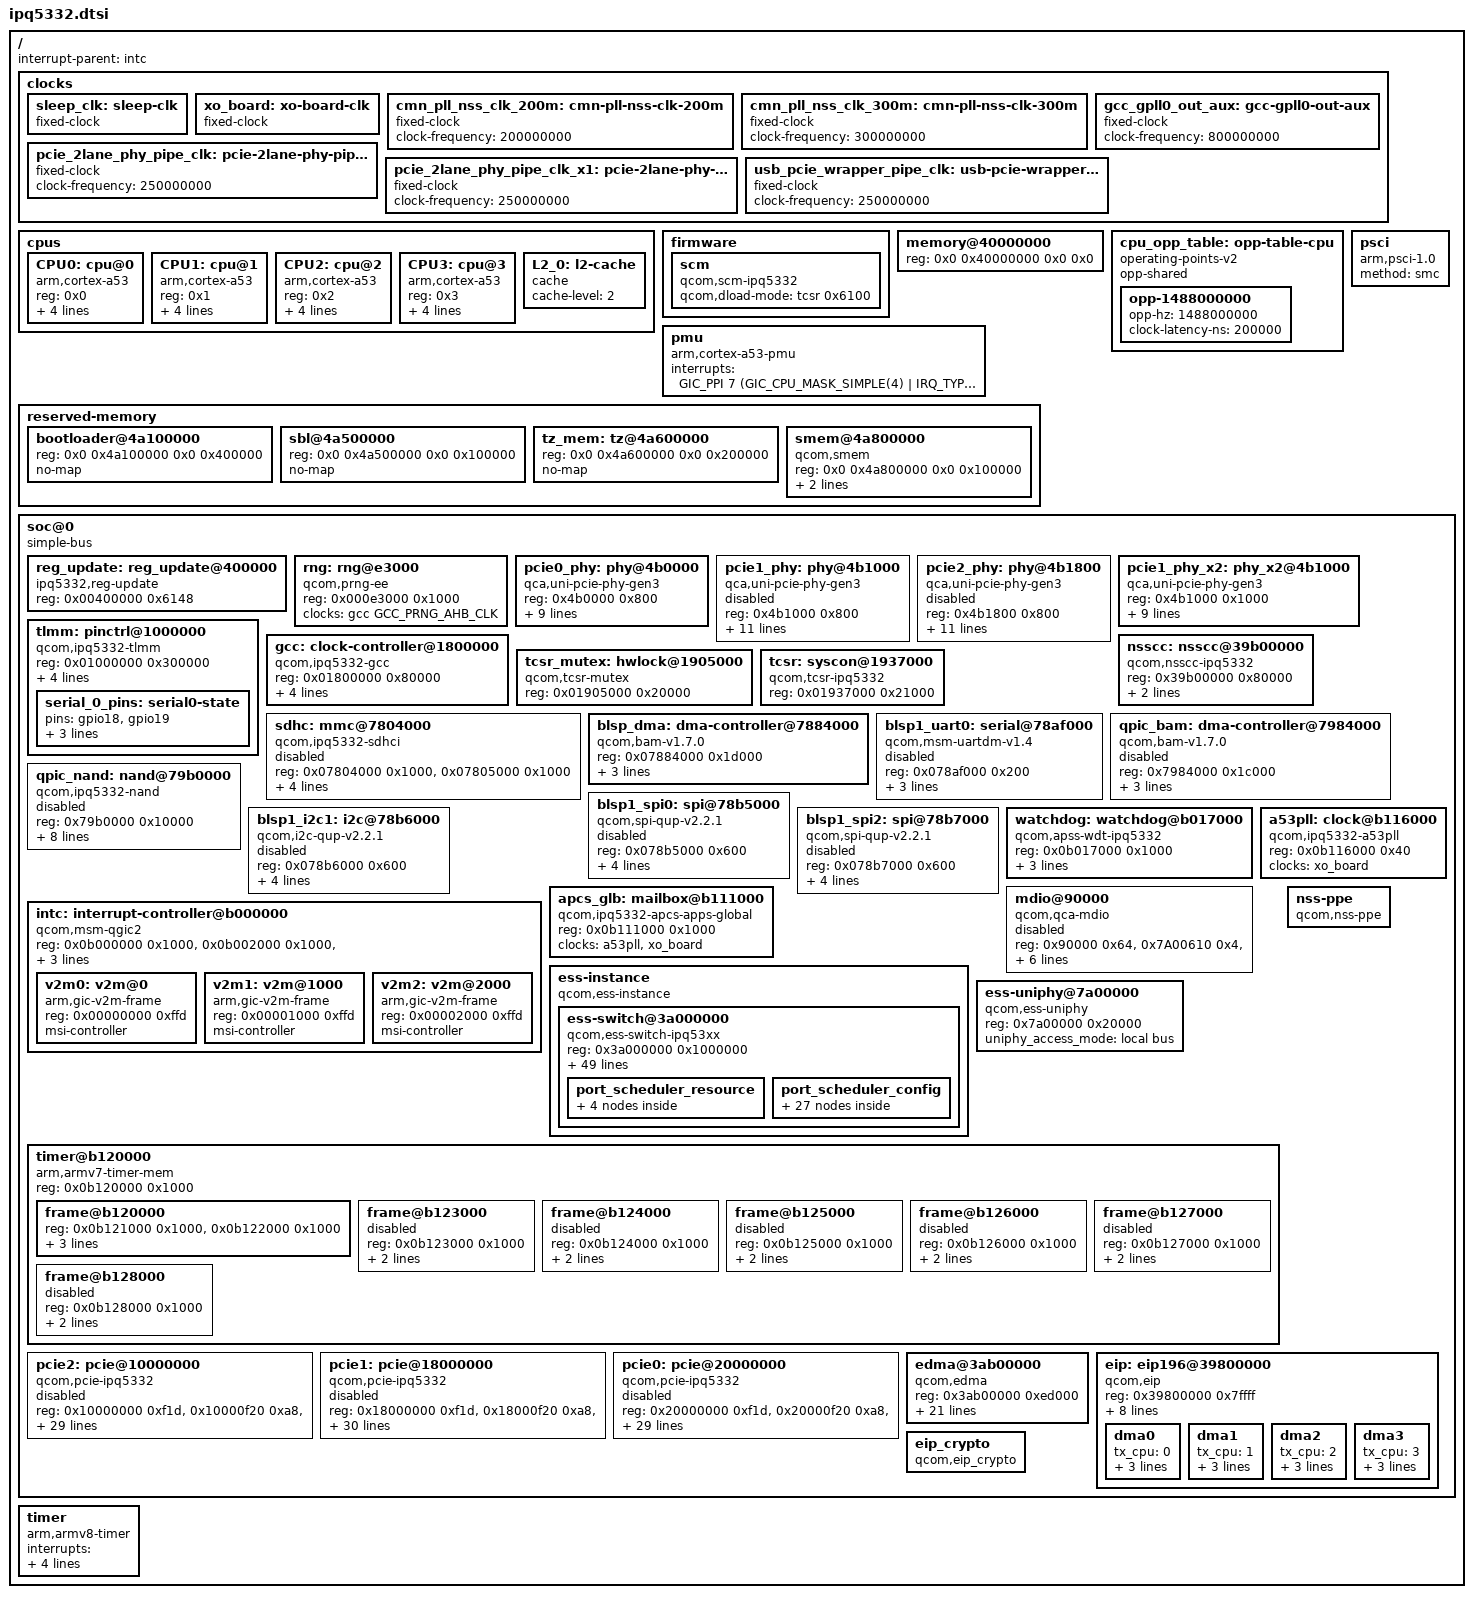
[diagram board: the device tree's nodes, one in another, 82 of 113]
// SPDX-License-Identifier: BSD-3-Clause
/*
 * IPQ5332 device tree source
 *
 * Copyright (c) 2022-2023 Qualcomm Innovation Center, Inc. All rights reserved.
 */

#include <dt-bindings/clock/qcom,apss-ipq.h>
#include <dt-bindings/clock/qcom,ipq5332-gcc.h>
#include <dt-bindings/clock/qcom,nsscc-ipq5332.h>
#include <dt-bindings/reset/qcom,nsscc-ipq5332.h>
#include <dt-bindings/interrupt-controller/arm-gic.h>

/ {
	interrupt-parent = <&intc>;
	#address-cells = <2>;
	#size-cells = <2>;

	clocks {
		sleep_clk: sleep-clk {
			compatible = "fixed-clock";
			#clock-cells = <0>;
		};

		xo_board: xo-board-clk {
			compatible = "fixed-clock";
			#clock-cells = <0>;
		};

		cmn_pll_nss_clk_200m: cmn-pll-nss-clk-200m {
			compatible = "fixed-clock";
			clock-frequency = <200000000>;
			#clock-cells = <0>;
		};

		cmn_pll_nss_clk_300m: cmn-pll-nss-clk-300m {
			compatible = "fixed-clock";
			clock-frequency = <300000000>;
			#clock-cells = <0>;
		};

		gcc_gpll0_out_aux: gcc-gpll0-out-aux {
			compatible = "fixed-clock";
			clock-frequency = <800000000>;
			#clock-cells = <0>;
		};

		pcie_2lane_phy_pipe_clk: pcie-2lane-phy-pipe-clk {
			compatible = "fixed-clock";
			clock-frequency = <250000000>;
			#clock-cells = <0>;
		};

		pcie_2lane_phy_pipe_clk_x1: pcie-2lane-phy-pipe-clk-x1 {
			compatible = "fixed-clock";
			clock-frequency = <250000000>;
			#clock-cells = <0>;
		};

		usb_pcie_wrapper_pipe_clk: usb-pcie-wrapper-pipe-clk {
			compatible = "fixed-clock";
			clock-frequency = <250000000>;
			#clock-cells = <0>;
		};
	};

	cpus {
		#address-cells = <1>;
		#size-cells = <0>;

		CPU0: cpu@0 {
			device_type = "cpu";
			compatible = "arm,cortex-a53";
			reg = <0x0>;
			enable-method = "psci";
			next-level-cache = <&L2_0>;
			clocks = <&apcs_glb APCS_ALIAS0_CORE_CLK>;
			operating-points-v2 = <&cpu_opp_table>;
		};

		CPU1: cpu@1 {
			device_type = "cpu";
			compatible = "arm,cortex-a53";
			reg = <0x1>;
			enable-method = "psci";
			next-level-cache = <&L2_0>;
			clocks = <&apcs_glb APCS_ALIAS0_CORE_CLK>;
			operating-points-v2 = <&cpu_opp_table>;
		};

		CPU2: cpu@2 {
			device_type = "cpu";
			compatible = "arm,cortex-a53";
			reg = <0x2>;
			enable-method = "psci";
			next-level-cache = <&L2_0>;
			clocks = <&apcs_glb APCS_ALIAS0_CORE_CLK>;
			operating-points-v2 = <&cpu_opp_table>;
		};

		CPU3: cpu@3 {
			device_type = "cpu";
			compatible = "arm,cortex-a53";
			reg = <0x3>;
			enable-method = "psci";
			next-level-cache = <&L2_0>;
			clocks = <&apcs_glb APCS_ALIAS0_CORE_CLK>;
			operating-points-v2 = <&cpu_opp_table>;
		};

		L2_0: l2-cache {
			compatible = "cache";
			cache-level = <2>;
		};
	};

	firmware {
		scm {
			compatible = "qcom,scm-ipq5332", "qcom,scm";
			qcom,dload-mode = <&tcsr 0x6100>;
		};
	};

	memory@40000000 {
		device_type = "memory";
		/* We expect the bootloader to fill in the size */
		reg = <0x0 0x40000000 0x0 0x0>;
	};

	cpu_opp_table: opp-table-cpu {
		compatible = "operating-points-v2";
		opp-shared;

		opp-1488000000 {
			opp-hz = /bits/ 64 <1488000000>;
			clock-latency-ns = <200000>;
		};
	};

	pmu {
		compatible = "arm,cortex-a53-pmu";
		interrupts = <GIC_PPI 7 (GIC_CPU_MASK_SIMPLE(4) | IRQ_TYPE_LEVEL_HIGH)>;
	};

	psci {
		compatible = "arm,psci-1.0";
		method = "smc";
	};

	reserved-memory {
		#address-cells = <2>;
		#size-cells = <2>;
		ranges;

		bootloader@4a100000 {
			reg = <0x0 0x4a100000 0x0 0x400000>;
			no-map;
		};

		sbl@4a500000 {
			reg = <0x0 0x4a500000 0x0 0x100000>;
			no-map;
		};

		tz_mem: tz@4a600000 {
			reg = <0x0 0x4a600000 0x0 0x200000>;
			no-map;
		};

		smem@4a800000 {
			compatible = "qcom,smem";
			reg = <0x0 0x4a800000 0x0 0x100000>;
			no-map;

			hwlocks = <&tcsr_mutex 0>;
		};
	};

	soc@0 {
		compatible = "simple-bus";
		#address-cells = <1>;
		#size-cells = <1>;
		ranges = <0 0 0 0xffffffff>;

		reg_update: reg_update@400000 {
			compatible = "ipq5332,reg-update";
			reg = <0x00400000 0x6148>;
			reg-names = "memnoc";
			status = "ok";
		};

		rng: rng@e3000 {
			compatible = "qcom,prng-ee";
			reg = <0x000e3000 0x1000>;
			clocks = <&gcc GCC_PRNG_AHB_CLK>;
			clock-names = "core";
		};

		pcie0_phy: phy@4b0000 {
			compatible = "qca,uni-pcie-phy-gen3";
			reg = <0x4b0000 0x800>;
			phy-type = "gen3";
			#phy-cells = <0>;
			clocks = <&gcc GCC_PCIE3X1_0_PIPE_CLK>,
				<&gcc GCC_SNOC_PCIE3_1LANE_M_CLK>,
				<&gcc GCC_SNOC_PCIE3_1LANE_S_CLK>,
				<&gcc GCC_PCIE3X1_PHY_AHB_CLK>;

			clock-names = "pipe_clk",
					"lane_m_clk",
					"lane_s_clk",
					"phy_ahb_clk";

			resets = <&gcc GCC_PCIE3X1_0_PHY_BCR>,
				<&gcc GCC_PCIE3X1_0_PHY_PHY_BCR>,
				<&gcc GCC_PCIE3X1_PHY_AHB_CLK_ARES>;
			reset-names = "phy",
					"phy_phy",
					"phy_ahb";
			mode-fixed = <2>; /* TBD */
			/*status = "disabled";*/
		};

		/* PHY for PCIE1 single lane mode */
		pcie1_phy: phy@4b1000 {
			compatible = "qca,uni-pcie-phy-gen3";
			reg = <0x4b1000 0x800>;
			phy-type = "gen3";
			#phy-cells = <0>;
			qti,multiplexed-phy;
			qti,phy-mux-regs = <&tcsr 0x10544>;
			phy-ahb-shared-reset;
			clocks = <&gcc GCC_PCIE3X2_PIPE_CLK>,
				<&gcc GCC_SNOC_PCIE3_2LANE_M_CLK>,
				<&gcc GCC_SNOC_PCIE3_2LANE_S_CLK>,
				<&gcc GCC_PCIE3X2_PHY_AHB_CLK>;

			clock-names = "pipe_clk",
					"lane_m_clk",
					"lane_s_clk",
					"phy_ahb_clk";

			resets = <&gcc GCC_PCIE3X2_PHY_BCR>,
				<&gcc GCC_PCIE3X2_PHY_AHB_CLK_ARES>;
			reset-names = "phy",
					"phy_ahb";
			mode-fixed = <2>; /* TBD */
			status = "disabled";
		};

		/* PHY for PCIE2 single lane mode */
		pcie2_phy: phy@4b1800 {
			compatible = "qca,uni-pcie-phy-gen3";
			reg = <0x4b1800 0x800>;
			phy-type = "gen3";
			#phy-cells = <0>;
			phy-ahb-shared-reset;

			qti,multiplexed-phy;
			qti,phy-mux-regs = <&tcsr 0x10544>;

			clocks = <&gcc GCC_PCIE3X1_1_PIPE_CLK>,
				<&gcc GCC_SNOC_PCIE3_1LANE_1_M_CLK>,
				<&gcc GCC_SNOC_PCIE3_1LANE_1_S_CLK>,
				<&gcc GCC_PCIE3X2_PHY_AHB_CLK>;

			clock-names = "pipe_clk",
					"lane_m_clk",
					"lane_s_clk",
					"phy_ahb_clk";

			resets = <&gcc GCC_PCIE3X1_1_PHY_BCR>,
				<&gcc GCC_PCIE3X2_PHY_AHB_CLK_ARES>;
			reset-names = "phy",
					"phy_ahb";
			mode-fixed = <2>; /* TBD */
			status = "disabled";
		};

		/* PHY for PCIE1 dual lane mode */
		pcie1_phy_x2: phy_x2@4b1000 {
			compatible = "qca,uni-pcie-phy-gen3";
			reg = <0x4b1000 0x1000>;
			phy-type = "gen3";
			#phy-cells = <0>;
			clocks = <&gcc GCC_PCIE3X2_PIPE_CLK>,
				<&gcc GCC_SNOC_PCIE3_2LANE_M_CLK>,
				<&gcc GCC_SNOC_PCIE3_2LANE_S_CLK>,
				<&gcc GCC_PCIE3X2_PHY_AHB_CLK>;

			clock-names = "pipe_clk",
					"lane_m_clk",
					"lane_s_clk",
					"phy_ahb_clk";

			resets = <&gcc GCC_PCIE3X2_PHY_BCR>,
				<&gcc GCC_PCIE3X2_PHY_AHB_CLK_ARES>;
			reset-names = "phy",
					"phy_ahb";
			mode-fixed = <2>; /* TBD */
			x2 = <1>;
			/*status = "disabled";*/
		};

		tlmm: pinctrl@1000000 {
			compatible = "qcom,ipq5332-tlmm";
			reg = <0x01000000 0x300000>;
			interrupts = <GIC_SPI 249 IRQ_TYPE_LEVEL_HIGH>;
			gpio-controller;
			#gpio-cells = <2>;
			gpio-ranges = <&tlmm 0 0 53>;
			interrupt-controller;
			#interrupt-cells = <2>;

			serial_0_pins: serial0-state {
				pins = "gpio18", "gpio19";
				function = "blsp0_uart0";
				drive-strength = <8>;
				bias-pull-up;
			};
		};

		gcc: clock-controller@1800000 {
			compatible = "qcom,ipq5332-gcc";
			reg = <0x01800000 0x80000>;
			#clock-cells = <1>;
			#reset-cells = <1>;
			#power-domain-cells = <1>;
			clocks = <&xo_board>,
				 <&sleep_clk>,
				 <&pcie_2lane_phy_pipe_clk>,
				 <&pcie_2lane_phy_pipe_clk_x1>,
				 <&usb_pcie_wrapper_pipe_clk>;
		};

		nsscc: nsscc@39b00000{
			compatible = "qcom,nsscc-ipq5332";
			reg = <0x39b00000 0x80000>;
			clocks = <&xo_board>,
				<&cmn_pll_nss_clk_200m>,
				<&cmn_pll_nss_clk_300m>,
				<&gcc_gpll0_out_aux>;
			clock-names = "xo",
					"cmn_pll_nss_clk_200m",
					"cmn_pll_nss_clk_300m",
					"gcc_gpll0_out_aux";
			#clock-cells = <0x1>;
			#reset-cells = <0x1>;
		};

		tcsr_mutex: hwlock@1905000 {
			compatible = "qcom,tcsr-mutex";
			reg = <0x01905000 0x20000>;
			#hwlock-cells = <1>;
		};

		tcsr: syscon@1937000 {
			compatible = "qcom,tcsr-ipq5332", "syscon";
			reg = <0x01937000 0x21000>;
		};

		sdhc: mmc@7804000 {
			compatible = "qcom,ipq5332-sdhci", "qcom,sdhci-msm-v5";
			reg = <0x07804000 0x1000>, <0x07805000 0x1000>;

			interrupts = <GIC_SPI 313 IRQ_TYPE_LEVEL_HIGH>,
				     <GIC_SPI 316 IRQ_TYPE_LEVEL_HIGH>;
			interrupt-names = "hc_irq", "pwr_irq";

			clocks = <&gcc GCC_SDCC1_AHB_CLK>,
				 <&gcc GCC_SDCC1_APPS_CLK>,
				 <&xo_board>;
			clock-names = "iface", "core", "xo";
			status = "disabled";
		};

		blsp_dma: dma-controller@7884000 {
			compatible = "qcom,bam-v1.7.0";
			reg = <0x07884000 0x1d000>;
			interrupts = <GIC_SPI 289 IRQ_TYPE_LEVEL_HIGH>;
			clocks = <&gcc GCC_BLSP1_AHB_CLK>;
			clock-names = "bam_clk";
			#dma-cells = <1>;
			qcom,ee = <0>;
		};

		blsp1_uart0: serial@78af000 {
			compatible = "qcom,msm-uartdm-v1.4", "qcom,msm-uartdm";
			reg = <0x078af000 0x200>;
			interrupts = <GIC_SPI 290 IRQ_TYPE_LEVEL_HIGH>;
			clocks = <&gcc GCC_BLSP1_UART1_APPS_CLK>,
				 <&gcc GCC_BLSP1_AHB_CLK>;
			clock-names = "core", "iface";
			status = "disabled";
		};

		qpic_bam: dma-controller@7984000 {
			compatible = "qcom,bam-v1.7.0";
			reg = <0x7984000 0x1c000>;
			interrupts = <GIC_SPI 66 IRQ_TYPE_LEVEL_HIGH>;
			clocks = <&gcc GCC_QPIC_AHB_CLK>;
			clock-names = "bam_clk";
			#dma-cells = <1>;
			qcom,ee = <0>;
			status = "disabled";
		};

		qpic_nand: nand@79b0000 {
			compatible = "qcom,ipq5332-nand";
			reg = <0x79b0000 0x10000>;
			#address-cells = <1>;
			#size-cells = <0>;
			clocks = <&gcc GCC_QPIC_CLK>,
				<&gcc GCC_QPIC_AHB_CLK>,
				<&gcc GCC_QPIC_IO_MACRO_CLK>;
			clock-names = "core", "aon", "io_macro";

			dmas = <&qpic_bam 0>,
				<&qpic_bam 1>,
				<&qpic_bam 2>,
				<&qpic_bam 3>;
			dma-names = "tx", "rx", "cmd", "sts";
			qcom,io_macro_max_clk = <320000000>;
			qcom,io_macro_clk_rates = <24000000 100000000 200000000 \
						  320000000>;
			status = "disabled";
		};

		blsp1_spi0: spi@78b5000 {
			compatible = "qcom,spi-qup-v2.2.1";
			reg = <0x078b5000 0x600>;
			#address-cells = <1>;
			#size-cells = <0>;
			interrupts = <GIC_SPI 292 IRQ_TYPE_LEVEL_HIGH>;
			clocks = <&gcc GCC_BLSP1_QUP1_SPI_APPS_CLK>,
			         <&gcc GCC_BLSP1_AHB_CLK>;
			clock-names = "core", "iface";
			dmas = <&blsp_dma 4>, <&blsp_dma 5>;
			dma-names = "tx", "rx";
			status = "disabled";
		};

		blsp1_i2c1: i2c@78b6000 {
			compatible = "qcom,i2c-qup-v2.2.1";
			reg = <0x078b6000 0x600>;
			#address-cells = <1>;
			#size-cells = <0>;
			interrupts = <GIC_SPI 293 IRQ_TYPE_LEVEL_HIGH>;
			clocks = <&gcc GCC_BLSP1_QUP2_I2C_APPS_CLK>,
			         <&gcc GCC_BLSP1_AHB_CLK>;
			clock-names = "core", "iface";
			dmas = <&blsp_dma 6>, <&blsp_dma 7>;
			dma-names = "tx", "rx";
			status = "disabled";
		};

		blsp1_spi2: spi@78b7000 {
			compatible = "qcom,spi-qup-v2.2.1";
			reg = <0x078b7000 0x600>;
			#address-cells = <1>;
			#size-cells = <0>;
			interrupts = <GIC_SPI 294 IRQ_TYPE_LEVEL_HIGH>;
			clocks = <&gcc GCC_BLSP1_QUP3_SPI_APPS_CLK>,
				 <&gcc GCC_BLSP1_AHB_CLK>;
			clock-names = "core", "iface";
			dmas = <&blsp_dma 8>, <&blsp_dma 9>;
			dma-names = "tx", "rx";
			status = "disabled";
		};

		intc: interrupt-controller@b000000 {
			compatible = "qcom,msm-qgic2";
			reg = <0x0b000000 0x1000>,	/* GICD */
			      <0x0b002000 0x1000>,	/* GICC */
			      <0x0b001000 0x1000>,	/* GICH */
			      <0x0b004000 0x1000>;	/* GICV */
			interrupts = <GIC_PPI 9 IRQ_TYPE_LEVEL_HIGH>;
			interrupt-controller;
			#interrupt-cells = <3>;
			#address-cells = <1>;
			#size-cells = <1>;
			ranges = <0 0x0b00c000 0x3000>;

			v2m0: v2m@0 {
				compatible = "arm,gic-v2m-frame";
				reg = <0x00000000 0xffd>;
				msi-controller;
			};

			v2m1: v2m@1000 {
				compatible = "arm,gic-v2m-frame";
				reg = <0x00001000 0xffd>;
				msi-controller;
			};

			v2m2: v2m@2000 {
				compatible = "arm,gic-v2m-frame";
				reg = <0x00002000 0xffd>;
				msi-controller;
			};
		};

		watchdog: watchdog@b017000 {
			compatible = "qcom,apss-wdt-ipq5332", "qcom,kpss-wdt";
			reg = <0x0b017000 0x1000>;
			interrupts = <GIC_SPI 3 IRQ_TYPE_EDGE_RISING>;
			clocks = <&sleep_clk>;
			timeout-sec = <30>;
		};

		apcs_glb: mailbox@b111000 {
			compatible = "qcom,ipq5332-apcs-apps-global",
				     "qcom,ipq6018-apcs-apps-global";
			reg = <0x0b111000 0x1000>;
			#clock-cells = <1>;
			clocks = <&a53pll>, <&xo_board>;
			clock-names = "pll", "xo";
			#mbox-cells = <1>;
		};

		a53pll: clock@b116000 {
			compatible = "qcom,ipq5332-a53pll";
			reg = <0x0b116000 0x40>;
			#clock-cells = <0>;
			clocks = <&xo_board>;
			clock-names = "xo";
		};

		mdio@90000 {
			compatible = "qcom,qca-mdio", "qcom,ipq40xx-mdio";
			reg = <0x90000 0x64>, <0x7A00610 0x4>, <0x7A10610 0x4>;
			#address-cells = <1>;
			#size-cells = <1>;
			clocks = <&gcc GCC_MDIO_AHB_CLK>,
			       <&gcc GCC_UNIPHY0_AHB_CLK>,
			       <&gcc GCC_UNIPHY0_SYS_CLK>,
			       <&gcc GCC_UNIPHY1_AHB_CLK>,
			       <&gcc GCC_UNIPHY1_SYS_CLK>;
			clock-names = "gcc_mdio_ahb_clk",
				"uniphy0_ahb_clk",
				"uniphy0_sys_clk",
				"uniphy1_ahb_clk",
				"uniphy1_sys_clk";
			status = "disabled";
		};

		ess-instance {
			compatible = "qcom,ess-instance";
			ess-switch@3a000000 {
				compatible = "qcom,ess-switch-ipq53xx";
				reg = <0x3a000000 0x1000000>;
				switch_access_mode = "local bus";
				bm_tick_mode = <0>; /* bm tick mode */
				tm_tick_mode = <0>; /* tm tick mode */
				clocks = <&gcc GCC_CMN_12GPLL_AHB_CLK>,
					<&gcc GCC_CMN_12GPLL_SYS_CLK>,
					<&gcc GCC_UNIPHY0_AHB_CLK>,
					<&gcc GCC_UNIPHY0_SYS_CLK>,
					<&gcc GCC_UNIPHY1_AHB_CLK>,
					<&gcc GCC_UNIPHY1_SYS_CLK>,
					<&gcc GCC_NSSNOC_NSSCC_CLK>,
					<&gcc GCC_NSSCC_CLK>,
					<&gcc GCC_NSSNOC_SNOC_1_CLK>,
					<&gcc GCC_NSSNOC_SNOC_CLK>,
					<&gcc GCC_IM_SLEEP_CLK>,
					<&nsscc NSS_CC_PORT1_MAC_CLK>,
					<&nsscc NSS_CC_PORT2_MAC_CLK>,
					<&nsscc NSS_CC_PPE_SWITCH_CLK>,
					<&nsscc NSS_CC_PPE_SWITCH_CFG_CLK>,
					<&nsscc NSS_CC_NSSNOC_PPE_CLK>,
					<&nsscc NSS_CC_NSSNOC_PPE_CFG_CLK>,
					<&nsscc NSS_CC_PPE_EDMA_CLK>,
					<&nsscc NSS_CC_PPE_EDMA_CFG_CLK>,
					<&nsscc NSS_CC_PPE_SWITCH_IPE_CLK>,
					<&nsscc NSS_CC_PPE_SWITCH_BTQ_CLK>,
					<&nsscc NSS_CC_PORT1_RX_CLK>,
					<&nsscc NSS_CC_PORT1_TX_CLK>,
					<&nsscc NSS_CC_PORT2_RX_CLK>,
					<&nsscc NSS_CC_PORT2_TX_CLK>,
					<&nsscc NSS_CC_UNIPHY_PORT1_RX_CLK>,
					<&nsscc NSS_CC_UNIPHY_PORT1_TX_CLK>,
					<&nsscc NSS_CC_UNIPHY_PORT2_RX_CLK>,
					<&nsscc NSS_CC_UNIPHY_PORT2_TX_CLK>;
				clock-names = "cmn_ahb_clk",
					"cmn_sys_clk",
					"uniphy0_ahb_clk",
					"uniphy0_sys_clk",
					"uniphy1_ahb_clk",
					"uniphy1_sys_clk",
					"gcc_nssnoc_nsscc_clk",
					"gcc_nsscc_clk",
					"gcc_nssnoc_snoc_1_clk",
					"gcc_nssnoc_snoc_clk",
					"gcc_im_sleep_clk",
					"port1_mac_clk",
					"port2_mac_clk",
					"nss_ppe_clk",
					"nss_ppe_cfg_clk",
					"nssnoc_ppe_clk",
					"nssnoc_ppe_cfg_clk",
					"nss_edma_clk",
					"nss_edma_cfg_clk",
					"nss_ppe_ipe_clk",
					"nss_ppe_btq_clk",
					"nss_port1_rx_clk",
					"nss_port1_tx_clk",
					"nss_port2_rx_clk",
					"nss_port2_tx_clk",
					"uniphy0_port1_rx_clk",
					"uniphy0_port1_tx_clk",
					"uniphy1_port5_rx_clk",
					"uniphy1_port5_tx_clk";
				resets = <&nsscc NSS_CC_PPE_BCR>,
					<&gcc GCC_UNIPHY0_BCR>,
					<&gcc GCC_UNIPHY1_BCR>,
					<&gcc GCC_UNIPHY0_AHB_CLK_ARES>,
					<&gcc GCC_UNIPHY1_AHB_CLK_ARES>,
					<&gcc GCC_UNIPHY0_SYS_CLK_ARES>,
					<&gcc GCC_UNIPHY1_SYS_CLK_ARES>,
					<&gcc GCC_UNIPHY0_XPCS_ARES>,
					<&gcc GCC_UNIPHY1_XPCS_ARES>,
					<&nsscc NSS_CC_UNIPHY_PORT1_RX_CLK_ARES>,
					<&nsscc NSS_CC_UNIPHY_PORT1_TX_CLK_ARES>,
					<&nsscc NSS_CC_UNIPHY_PORT2_RX_CLK_ARES>,
					<&nsscc NSS_CC_UNIPHY_PORT2_TX_CLK_ARES>,
					<&nsscc NSS_CC_PORT1_RX_CLK_ARES>,
					<&nsscc NSS_CC_PORT1_TX_CLK_ARES>,
					<&nsscc NSS_CC_PORT2_RX_CLK_ARES>,
					<&nsscc NSS_CC_PORT2_TX_CLK_ARES>,
					<&nsscc NSS_CC_PORT1_MAC_CLK_ARES>,
					<&nsscc NSS_CC_PORT2_MAC_CLK_ARES>;
				reset-names = "ppe_rst",
					"uniphy0_soft_rst",
					"uniphy1_soft_rst",
					"uniphy0_ahb_rst",
					"uniphy1_ahb_rst",
					"uniphy0_sys_rst",
					"uniphy1_sys_rst",
					"uniphy0_xpcs_rst",
					"uniphy1_xpcs_rst",
					"uniphy_port1_rx_rst",
					"uniphy_port1_tx_rst",
					"uniphy_port2_rx_rst",
					"uniphy_port2_tx_rst",
					"nss_port1_rx_rst",
					"nss_port1_tx_rst",
					"nss_port2_rx_rst",
					"nss_port2_tx_rst",
					"nss_port1_mac_rst",
					"nss_port2_mac_rst";

				port_scheduler_resource {
					port@0 {
						port_id = <0>;
						ucast_queue = <0 43>;
						mcast_queue = <256 262>;
						l0sp = <0 6>;
						l0cdrr = <0 27>;
						l0edrr = <0 27>;
						l1cdrr = <0 0>;
						l1edrr = <0 0>;
					};
					port@1 {
						port_id = <1>;
						ucast_queue = <204 211>;
						mcast_queue = <272 275>;
						l0sp = <51 52>;
						l0cdrr = <108 115>;
						l0edrr = <108 115>;
						l1cdrr = <23 24>;
						l1edrr = <23 24>;
					};
					port@2 {
						port_id = <2>;
						ucast_queue = <212 219>;
						mcast_queue = <276 279>;
						l0sp = <53 54>;
						l0cdrr = <116 123>;
						l0edrr = <116 123>;
						l1cdrr = <25 26>;
						l1edrr = <25 26>;
					};
					reserved {
						ucast_queue = <44 203>;
						mcast_queue = <263 271>;
						l0sp = <7 50>;
						l0cdrr = <28 107>;
						l0edrr = <28 107>;
						l1cdrr = <1 22>;
						l1edrr = <1 22>;
					};
				};

				port_scheduler_config {
					port@0 {
						port_id = <0>;
						l1scheduler {
							group@0 {
								/* L0 SP */
								sp = <0 1 2 3 4 5 6>;
								/* cpri cdrr epri edrr */
								cfg = <0 0 0 0>;
							};
						};
						l0scheduler {
							group@0 {
								/* unicast queue */
								ucast_queue = <0>;
								ucast_loop_pri = <4>;
								/* multicast queue */
								mcast_queue = <256>;
								/* sp cpri cdrr epri edrr */
								cfg = <0 0 0 0 0>;
							};
							group@1 {
								ucast_queue = <4>;
								ucast_loop_pri = <4>;
								cfg = <0 0 0 0 0>;
							};
							group@2 {
								ucast_queue = <8>;
								ucast_loop_pri = <4>;
								mcast_queue = <257>;
								cfg = <1 0 4 0 4>;
							};
							group@3 {
								ucast_queue = <12>;
								ucast_loop_pri = <4>;
								cfg = <1 0 4 0 4>;
							};
							group@4 {
								ucast_queue = <16>;
								ucast_loop_pri = <4>;
								mcast_queue = <258>;
								cfg = <2 0 8 0 8>;
							};
							group@5 {
								ucast_queue = <20>;
								ucast_loop_pri = <4>;
								cfg = <2 0 8 0 8>;
							};
							group@6 {
								ucast_queue = <24>;
								ucast_loop_pri = <4>;
								mcast_queue = <259>;
								cfg = <3 0 12 0 12>;
							};
							group@7 {
								ucast_queue = <28>;
								ucast_loop_pri = <4>;
								cfg = <3 0 12 0 12>;
							};
							group@8 {
								ucast_queue = <32>;
								ucast_loop_pri = <4>;
								mcast_queue = <260>;
								cfg = <4 0 16 0 16>;
							};
							group@9 {
								ucast_queue = <36>;
								ucast_loop_pri = <4>;
								mcast_queue = <261>;
								cfg = <5 0 20 0 20>;
							};
							group@10 {
								ucast_queue = <40>;
								ucast_loop_pri = <4>;
								mcast_queue = <262>;
								cfg = <6 0 24 0 24>;
							};
						};
					};
					port@1 {
						port_id = <1>;
						l1scheduler {
							group@0 {
								sp = <51>;
								cfg = <0 23 0 23>;
							};
							group@1 {
								sp = <52>;
								cfg = <1 24 1 24>;
							};
						};
						l0scheduler {
							group@0 {
								ucast_queue = <204>;
								ucast_loop_pri = <8>;
								/* max priority per SP */
								ucast_max_pri = <4>;
								mcast_queue = <272>;
								mcast_loop_pri = <4>;
								cfg = <51 0 108 0 108>;
							};
						};
					};
					port@2 {
						port_id = <2>;
						l1scheduler {
							group@0 {
								sp = <53>;
								cfg = <0 25 0 25>;
							};
							group@1 {
								sp = <54>;
								cfg = <1 26 1 26>;
							};
						};
						l0scheduler {
							group@0 {
								ucast_queue = <212>;
								ucast_loop_pri = <8>;
								ucast_max_pri = <4>;
								mcast_queue = <276>;
								mcast_loop_pri = <4>;
								cfg = <53 0 116 0 116>;
							};
						};
					};
				};
			};
		};

		ess-uniphy@7a00000 {
			compatible = "qcom,ess-uniphy";
			reg = <0x7a00000 0x20000>;
			uniphy_access_mode = "local bus";
		};

		timer@b120000 {
			compatible = "arm,armv7-timer-mem";
			reg = <0x0b120000 0x1000>;
			#address-cells = <1>;
			#size-cells = <1>;
			ranges;

			frame@b120000 {
				reg = <0x0b121000 0x1000>,
				      <0x0b122000 0x1000>;
				interrupts = <GIC_SPI 8 IRQ_TYPE_LEVEL_HIGH>,
					     <GIC_SPI 7 IRQ_TYPE_LEVEL_HIGH>;
				frame-number = <0>;
			};

			frame@b123000 {
				reg = <0x0b123000 0x1000>;
				interrupts = <GIC_SPI 9 IRQ_TYPE_LEVEL_HIGH>;
				frame-number = <1>;
				status = "disabled";
			};

			frame@b124000 {
				reg = <0x0b124000 0x1000>;
				interrupts = <GIC_SPI 10 IRQ_TYPE_LEVEL_HIGH>;
				frame-number = <2>;
				status = "disabled";
			};

			frame@b125000 {
				reg = <0x0b125000 0x1000>;
				interrupts = <GIC_SPI 11 IRQ_TYPE_LEVEL_HIGH>;
				frame-number = <3>;
				status = "disabled";
			};

			frame@b126000 {
				reg = <0x0b126000 0x1000>;
				interrupts = <GIC_SPI 12 IRQ_TYPE_LEVEL_HIGH>;
				frame-number = <4>;
				status = "disabled";
			};

			frame@b127000 {
				reg = <0x0b127000 0x1000>;
				interrupts = <GIC_SPI 13 IRQ_TYPE_LEVEL_HIGH>;
				frame-number = <5>;
				status = "disabled";
			};

			frame@b128000 {
				reg = <0x0b128000 0x1000>;
				interrupts = <GIC_SPI 14 IRQ_TYPE_LEVEL_HIGH>;
				frame-number = <6>;
				status = "disabled";
			};
		};

		/* 1L controller with 2L/2x1L Flexible PHY 2nd lane */
		pcie2: pcie@10000000 {
			compatible = "qcom,pcie-ipq5332";
			reg =  <0x10000000 0xf1d>,
			       <0x10000f20 0xa8>,
			       <0x10001000 0x1000>,
			       <0xf0000 0x3000>,
			       <0x10100000 0x1000>,
			       <0x59C188 0x4>;
			reg-names = "dbi", "elbi", "atu", "parf", "config", "system_noc";
			device_type = "pci";
			linux,pci-domain = <2>;
			bus-range = <0x00 0xff>;
			num-lanes = <1>;
			#address-cells = <3>;
			#size-cells = <2>;
			axi-halt-val = <0x1e>; /* increase halt window size to 1GB */

			ranges = <0x81000000 0 0x10200000 0x10200000 0 0x00100000>,   /* downstream I/O */
				 <0x82000000 0 0x10300000 0x10300000 0 0x07d00000>; /* non-prefetchable memory */

			phys = <&pcie2_phy>;
			phy-names = "pciephy";

			#interrupt-cells = <1>;
			interrupt-map-mask = <0 0 0 0x7>;
			interrupt-map = <0 0 0 1 &intc 0 399 IRQ_TYPE_LEVEL_HIGH>, /* int_a */
					<0 0 0 2 &intc 0 400 IRQ_TYPE_LEVEL_HIGH>, /* int_b */
					<0 0 0 3 &intc 0 401 IRQ_TYPE_LEVEL_HIGH>, /* int_c */
					<0 0 0 4 &intc 0 402 IRQ_TYPE_LEVEL_HIGH>; /* int_d */

			interrupts = <GIC_SPI 49 IRQ_TYPE_LEVEL_HIGH>;
			interrupt-names = "global_irq";

			clocks = <&gcc GCC_PCIE3X1_1_AXI_M_CLK>,
				 <&gcc GCC_PCIE3X1_1_AXI_S_CLK>,
				 <&gcc GCC_PCIE3X1_1_AHB_CLK>,
				 <&gcc GCC_PCIE3X2_AUX_CLK>,
				 <&gcc GCC_PCIE3X1_1_AXI_S_BRIDGE_CLK>,
				 <&gcc GCC_PCIE3X1_1_RCHG_CLK>;

			clock-names = "axi_m",
				      "axi_s",
				      "ahb",
				      "aux",
				      "axi_bridge",
				      "rchng";

			resets = <&gcc GCC_PCIE3X1_1_PIPE_ARES>,
				 <&gcc GCC_PCIE3X1_1_CORE_STICKY_ARES>,
				 <&gcc GCC_PCIE3X1_1_AXI_M_CLK_ARES>,
				 <&gcc GCC_PCIE3X1_1_AXI_S_CLK_ARES>,
				 <&gcc GCC_PCIE3X1_1_AXI_M_STICKY_ARES>,
				 <&gcc GCC_PCIE3X1_1_AXI_S_STICKY_ARES>,
				 <&gcc GCC_PCIE3X1_1_AHB_CLK_ARES>,
				 <&gcc GCC_PCIE3X1_1_AUX_CLK_ARES>;

			reset-names = "pipe",
				      "sticky",
				      "axi_m",
				      "axi_s",
				      "axi_m_sticky",
				      "axi_s_sticky",
				      "ahb",
				      "aux";

			msi-parent = <&v2m0>;
			status = "disabled";
		};

		/* 2L controller with 2L/2x1L Flexible PHY.
		 * Connected to the 1st lane of the Flexible PHY in 1L mode
		 */
		pcie1: pcie@18000000 {
			compatible = "qcom,pcie-ipq5332";
			reg =  <0x18000000 0xf1d>,
			       <0x18000f20 0xa8>,
			       <0x18001000 0x1000>,
			       <0x88000 0x3000>,
			       <0x18100000 0x1000>,
			       <0x59C210 0x4>;
			reg-names = "dbi", "elbi", "atu", "parf", "config", "system_noc";
			device_type = "pci";
			linux,pci-domain = <1>;
			bus-range = <0x00 0xff>;
			num-lanes = <2>;
			#address-cells = <3>;
			#size-cells = <2>;
			slv-addr-space-sz = <0x8000000>;
			axi-halt-val = <0x1e>; /* increase halt window size to 1GB */

			phys = <&pcie1_phy_x2>;
			phy-names = "pciephy";

			ranges = <0x81000000 0 0x18200000 0x18200000 0 0x00100000>,   /* downstream I/O */
				 <0x82000000 0 0x18300000 0x18300000 0 0x07d00000>; /* non-prefetchable memory */

			#interrupt-cells = <1>;
			interrupt-map-mask = <0 0 0 0x7>;
			interrupt-map = <0 0 0 1 &intc 0 412 IRQ_TYPE_LEVEL_HIGH>, /* int_a */
					<0 0 0 2 &intc 0 413 IRQ_TYPE_LEVEL_HIGH>, /* int_b */
					<0 0 0 3 &intc 0 414 IRQ_TYPE_LEVEL_HIGH>, /* int_c */
					<0 0 0 4 &intc 0 415 IRQ_TYPE_LEVEL_HIGH>; /* int_d */

			interrupts = <GIC_SPI 411 IRQ_TYPE_LEVEL_HIGH>;
			interrupt-names = "global_irq";

			clocks = <&gcc GCC_PCIE3X2_AXI_M_CLK>,
				 <&gcc GCC_PCIE3X2_AXI_S_CLK>,
				 <&gcc GCC_PCIE3X2_AHB_CLK>,
				 <&gcc GCC_PCIE3X2_AUX_CLK>,
				 <&gcc GCC_PCIE3X2_AXI_S_BRIDGE_CLK>,
				 <&gcc GCC_PCIE3X2_RCHG_CLK>;

			clock-names = "axi_m",
				      "axi_s",
				      "ahb",
				      "aux",
				      "axi_bridge",
				      "rchng";

			resets = <&gcc GCC_PCIE3X2_PIPE_ARES>,
				 <&gcc GCC_PCIE3X2_CORE_STICKY_ARES>,
				 <&gcc GCC_PCIE3X2_AXI_M_CLK_ARES>,
				 <&gcc GCC_PCIE3X2_AXI_S_CLK_ARES>,
				 <&gcc GCC_PCIE3X2_AXI_M_STICKY_ARES>,
				 <&gcc GCC_PCIE3X2_AXI_S_STICKY_ARES>,
				 <&gcc GCC_PCIE3X2_AHB_CLK_ARES>,
				 <&gcc GCC_PCIE3X2_AUX_CLK_ARES>;

			reset-names = "pipe",
				      "sticky",
				      "axi_m",
				      "axi_s",
				      "axi_m_sticky",
				      "axi_s_sticky",
				      "ahb",
				      "aux";

			msi-parent = <&v2m0>;
			status = "disabled";
		};

		/* 1L controller with USB/PCIe combo PHY */
		pcie0: pcie@20000000 {
			compatible = "qcom,pcie-ipq5332";
			reg =  <0x20000000 0xf1d>,
			       <0x20000f20 0xa8>,
			       <0x20001000 0x1000>,
			       <0x80000 0x3000>,
			       <0x20100000 0x1000>,
			       <0x59C108 0x4>;
			reg-names = "dbi", "elbi", "atu", "parf", "config", "system_noc";
			device_type = "pci";
			linux,pci-domain = <0>;
			bus-range = <0x00 0xff>;
			num-lanes = <1>;
			#address-cells = <3>;
			#size-cells = <2>;
			axi-halt-val = <0x1e>; /* increase halt window size to 1GB */

			phys = <&pcie0_phy>;
			phy-names = "pciephy";

			ranges = <0x81000000 0 0x20200000 0x20200000 0 0x00100000>,   /* downstream I/O */
				 <0x82000000 0 0x20300000 0x20300000 0 0x0fd00000>; /* non-prefetchable memory */

			#interrupt-cells = <1>;
			interrupt-map-mask = <0 0 0 0x7>;
			interrupt-map = <0 0 0 1 &intc 0 35 IRQ_TYPE_LEVEL_HIGH>, /* int_a */
					<0 0 0 2 &intc 0 36 IRQ_TYPE_LEVEL_HIGH>, /* int_b */
					<0 0 0 3 &intc 0 37 IRQ_TYPE_LEVEL_HIGH>, /* int_c */
					<0 0 0 4 &intc 0 38 IRQ_TYPE_LEVEL_HIGH>; /* int_d */

			interrupts = <GIC_SPI 34 IRQ_TYPE_LEVEL_HIGH>;
			interrupt-names = "global_irq";

			clocks = <&gcc GCC_PCIE3X1_0_AXI_M_CLK>,
				 <&gcc GCC_PCIE3X1_0_AXI_S_CLK>,
				 <&gcc GCC_PCIE3X1_0_AHB_CLK>,
				 <&gcc GCC_PCIE3X1_0_AUX_CLK>,
				 <&gcc GCC_PCIE3X1_0_AXI_S_BRIDGE_CLK>,
				 <&gcc GCC_PCIE3X1_0_RCHG_CLK>;

			clock-names = "axi_m",
				      "axi_s",
				      "ahb",
				      "aux",
				      "axi_bridge",
				      "rchng";

			resets = <&gcc GCC_PCIE3X1_0_PIPE_ARES>,
				 <&gcc GCC_PCIE3X1_0_CORE_STICKY_ARES>,
				 <&gcc GCC_PCIE3X1_0_AXI_M_CLK_ARES>,
				 <&gcc GCC_PCIE3X1_0_AXI_S_CLK_ARES>,
				 <&gcc GCC_PCIE3X1_0_AXI_M_STICKY_ARES>,
				 <&gcc GCC_PCIE3X1_0_AXI_S_STICKY_ARES>,
				 <&gcc GCC_PCIE3X1_0_AHB_CLK_ARES>,
				 <&gcc GCC_PCIE3X1_0_AUX_CLK_ARES>;

			reset-names = "pipe",
				      "sticky",
				      "axi_m",
				      "axi_s",
				      "axi_m_sticky",
				      "axi_s_sticky",
				      "ahb",
				      "aux";

			msi-parent = <&v2m0>;
			status = "disabled";
		};

		edma@3ab00000 {
			compatible = "qcom,edma";
			reg = <0x3ab00000 0xed000>;
			reg-names = "edma-reg-base";
			reset-names = "edma_rst";
			clocks = <&nsscc NSS_CC_NSS_CSR_CLK>,
			       <&nsscc NSS_CC_NSSNOC_NSS_CSR_CLK>,
			       <&nsscc NSS_CC_CE_APB_CLK>,
			       <&nsscc NSS_CC_CE_AXI_CLK>,
			       <&nsscc NSS_CC_NSSNOC_CE_APB_CLK>,
			       <&nsscc NSS_CC_NSSNOC_CE_AXI_CLK>,
			       <&gcc GCC_NSS_TS_CLK>,
			       <&gcc GCC_NSSCC_CLK>,
			       <&gcc GCC_NSSCFG_CLK>,
			       <&gcc GCC_NSSNOC_ATB_CLK>,
			       <&gcc GCC_NSSNOC_NSSCC_CLK>,
			       <&gcc GCC_NSSNOC_PCNOC_1_CLK>,
			       <&gcc GCC_NSSNOC_QOSGEN_REF_CLK>,
			       <&gcc GCC_NSSNOC_SNOC_1_CLK>,
			       <&gcc GCC_NSSNOC_SNOC_CLK>,
			       <&gcc GCC_NSSNOC_TIMEOUT_REF_CLK>,
			       <&gcc GCC_NSSNOC_XO_DCD_CLK>,
			       <&gcc GCC_SNOC_NSSNOC_CLK>,
			       <&gcc GCC_SNOC_NSSNOC_1_CLK>,
			       <&gcc GCC_MEM_NOC_AHB_CLK>,
			       <&gcc GCC_MEM_NOC_APSS_AXI_CLK>,
			       <&gcc GCC_MEM_NOC_QOSGEN_EXTREF_CLK>,
			       <&gcc GCC_MEM_NOC_TS_CLK>;
			clock-names = "nss-csr-clk", "nss-nssnoc-csr-clk", "nss-ce-ahb-clk",
				"nss-ce-axi-clk", "nss-nssnoc-ce-ahb-clk", "nss-nssnoc-ce-axi-clk",
				"nss-ts-clk", "nss-nsscc-clk", "nss-nsscfg-clk", "nss-nssnoc-atb-clk",
				"nss-nssnoc-nsscc-clk", "nss-nssnoc-pcnoc-1-clk", "nss-nssnoc-qosgen-ref-clk",
				"nss-nssnoc-snoc-1-clk", "nss-nssnoc-snoc-clk", "nss-nssnoc-timeout-ref-clk",
				"nss-nssnoc-xo-dcd-clk", "nss-snoc-nssnoc-clk", "nss-snoc-nssnoc-1-clk",
				"nss-mem-noc-ahb-clk", "nss-mem-noc-apss-axi-clk",
				"nss-mem-noc-qosgen-extref-clk","nss-mem-noc-ts-clk";
		};

		nss-ppe {
			compatible = "qcom,nss-ppe";
		};

		eip: eip196@39800000 {
			compatible = "qcom,eip";
			reg-names = "eip_pbase";
			reg = <0x39800000 0x7ffff>;
			reg_offset = <0x80000>;
			ranges;
			clocks = <&nsscc NSS_CC_EIP_CLK>,
			       <&nsscc NSS_CC_NSSNOC_EIP_CLK>;
			clock-names = "eip_clk", "eip_nocclk";
			clock-frequency = /bits/ 64 <300000000 300000000>;
			status = "ok";
			interrupts = <GIC_SPI 107 IRQ_TYPE_LEVEL_HIGH>,
				   <GIC_SPI 108 IRQ_TYPE_LEVEL_HIGH>,
				   <GIC_SPI 109 IRQ_TYPE_LEVEL_HIGH>,
				   <GIC_SPI 110 IRQ_TYPE_LEVEL_HIGH>;

			dma0 {
				tx_cpu = /bits/ 8 <0>;
				rx_cpu = /bits/ 8 <3>;
				ring-name = "lookaside";
				ring-id = /bits/ 8 <0>;
			};

			dma1 {
				tx_cpu = /bits/ 8 <1>;
				rx_cpu = /bits/ 8 <2>;
				ring-name = "lookaside";
				ring-id = /bits/ 8 <1>;
			};

			dma2 {
				tx_cpu = /bits/ 8 <2>;
				rx_cpu = /bits/ 8 <1>;
				ring-name = "lookaside";
				ring-id = /bits/ 8 <2>;
			};

			dma3 {
				tx_cpu = /bits/ 8 <3>;
				rx_cpu = /bits/ 8 <0>;
				ring-name = "lookaside";
				ring-id = /bits/ 8 <3>;
			};
		};

		eip_crypto: eip_crypto {
			compatible = "qcom,eip_crypto";
			status = "ok";
		};
	};

	timer {
		compatible = "arm,armv8-timer";
		interrupts = <GIC_PPI 2 (GIC_CPU_MASK_SIMPLE(4) | IRQ_TYPE_LEVEL_LOW)>,
			     <GIC_PPI 3 (GIC_CPU_MASK_SIMPLE(4) | IRQ_TYPE_LEVEL_LOW)>,
			     <GIC_PPI 4 (GIC_CPU_MASK_SIMPLE(4) | IRQ_TYPE_LEVEL_LOW)>,
			     <GIC_PPI 1 (GIC_CPU_MASK_SIMPLE(4) | IRQ_TYPE_LEVEL_LOW)>;
	};
};
